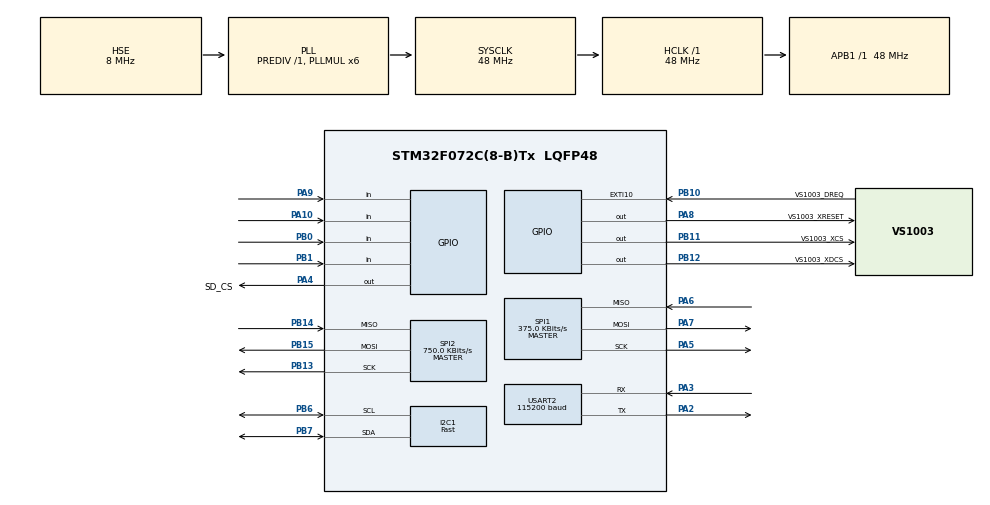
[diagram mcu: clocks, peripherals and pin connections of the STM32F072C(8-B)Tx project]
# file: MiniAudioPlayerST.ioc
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Dma.Request0=SPI1_RX
Dma.Request1=SPI1_TX
Dma.Request2=SPI2_TX
Dma.SPI1_RX.0.Direction=DMA_PERIPH_TO_MEMORY
Dma.SPI1_RX.0.Instance=DMA1_Channel2
Dma.SPI1_RX.0.MemDataAlignment=DMA_MDATAALIGN_BYTE
Dma.SPI1_RX.0.MemInc=DMA_MINC_ENABLE
Dma.SPI1_RX.0.Mode=DMA_NORMAL
Dma.SPI1_RX.0.PeriphDataAlignment=DMA_PDATAALIGN_BYTE
Dma.SPI1_RX.0.PeriphInc=DMA_PINC_DISABLE
Dma.SPI1_RX.0.Priority=DMA_PRIORITY_HIGH
Dma.SPI1_TX.1.Direction=DMA_MEMORY_TO_PERIPH
Dma.SPI1_TX.1.Instance=DMA1_Channel3
Dma.SPI1_TX.1.MemDataAlignment=DMA_MDATAALIGN_BYTE
Dma.SPI1_TX.1.MemInc=DMA_MINC_DISABLE
Dma.SPI1_TX.1.Mode=DMA_NORMAL
Dma.SPI1_TX.1.PeriphDataAlignment=DMA_PDATAALIGN_BYTE
Dma.SPI1_TX.1.PeriphInc=DMA_PINC_DISABLE
Dma.SPI1_TX.1.Priority=DMA_PRIORITY_HIGH
Dma.SPI2_TX.2.Direction=DMA_MEMORY_TO_PERIPH
Dma.SPI2_TX.2.Instance=DMA1_Channel5
Dma.SPI2_TX.2.MemDataAlignment=DMA_MDATAALIGN_BYTE
Dma.SPI2_TX.2.MemInc=DMA_MINC_ENABLE
Dma.SPI2_TX.2.Mode=DMA_NORMAL
Dma.SPI2_TX.2.PeriphDataAlignment=DMA_PDATAALIGN_BYTE
Dma.SPI2_TX.2.PeriphInc=DMA_PINC_DISABLE
Dma.SPI2_TX.2.Priority=DMA_PRIORITY_VERY_HIGH
FATFS._CODE_PAGE=437
FATFS._FS_NORTC=1
FATFS._LFN_UNICODE=1
FATFS._NORTC_MDAY=24
FATFS._NORTC_MON=6
FATFS._NORTC_YEAR=2026
FATFS._USE_FASTSEEK=0
FATFS._USE_LFN=1
FATFS._USE_MKFS=0
FATFS._USE_STRFUNC=0
I2C1.I2C_Speed_Mode=I2C_Fast
I2C1.Timing=0x0010020A
Mcu.Family=STM32F0
Mcu.Name=STM32F072C(8-B)Tx
Mcu.Package=LQFP48
NVIC.DMA1_Channel2_3_IRQn=true\:2\:0\:true\:false\:true\:false\:true\:true
NVIC.DMA1_Channel4_5_6_7_IRQn=true\:1\:0\:true\:false\:true\:false\:true\:true
NVIC.EXTI4_15_IRQn=true\:0\:0\:true\:false\:true\:true\:true\:true
NVIC.TIM1_BRK_UP_TRG_COM_IRQn=true\:3\:0\:true\:false\:true\:true\:true\:true
PA10.GPIO_PuPd=GPIO_PULLUP
PA10.Signal=GPIO_Input
PA13.Mode=Serial_Wire
PA13.Signal=SYS_SWDIO
PA14.Mode=Serial_Wire
PA14.Signal=SYS_SWCLK
PA2.Mode=Asynchronous
PA2.Signal=USART2_TX
PA3.Mode=Asynchronous
PA3.Signal=USART2_RX
PA4.GPIO_Label=SD_CS
PA4.PinState=GPIO_PIN_SET
PA4.Signal=GPIO_Output
PA5.Mode=Full_Duplex_Master
PA5.Signal=SPI1_SCK
PA6.Mode=Full_Duplex_Master
PA6.Signal=SPI1_MISO
PA7.Mode=Full_Duplex_Master
PA7.Signal=SPI1_MOSI
PA8.GPIO_Label=VS1003_XRESET
PA8.Signal=GPIO_Output
PA9.GPIO_PuPd=GPIO_PULLUP
PA9.Signal=GPIO_Input
PB0.GPIO_PuPd=GPIO_PULLUP
PB0.Signal=GPIO_Input
PB1.GPIO_PuPd=GPIO_PULLUP
PB1.Signal=GPIO_Input
PB10.GPIO_Label=VS1003_DREQ
PB10.Signal=GPXTI10
PB11.GPIO_Label=VS1003_XCS
PB11.GPIO_PuPd=GPIO_NOPULL
PB11.PinState=GPIO_PIN_SET
PB11.Signal=GPIO_Output
PB12.GPIO_Label=VS1003_XDCS
PB12.PinState=GPIO_PIN_SET
PB12.Signal=GPIO_Output
PB13.Mode=Full_Duplex_Master
PB13.Signal=SPI2_SCK
PB14.Mode=Full_Duplex_Master
PB14.Signal=SPI2_MISO
PB15.Mode=Full_Duplex_Master
PB15.Signal=SPI2_MOSI
PB6.Mode=I2C
PB6.Signal=I2C1_SCL
PB7.Mode=I2C
PB7.Signal=I2C1_SDA
PF0-OSC_IN.Mode=HSE-External-Oscillator
PF0-OSC_IN.Signal=RCC_OSC_IN
PF1-OSC_OUT.Mode=HSE-External-Oscillator
PF1-OSC_OUT.Signal=RCC_OSC_OUT
ProjectManager.HeapSize=0x200
ProjectManager.StackSize=0x800
ProjectManager.TargetToolchain=MDK-ARM V5.32
RCC.AHBFreq_Value=48000000
RCC.APB1Freq_Value=48000000
RCC.APB1TimFreq_Value=48000000
RCC.HCLKFreq_Value=48000000
RCC.PLLMUL=RCC_PLL_MUL6
RCC.PLLSourceVirtual=RCC_PLLSOURCE_HSE
RCC.SYSCLKFreq_VALUE=48000000
RCC.SYSCLKSource=RCC_SYSCLKSOURCE_PLLCLK
SPI1.BaudRatePrescaler=SPI_BAUDRATEPRESCALER_128
SPI1.CalculateBaudRate=375.0 KBits/s
SPI1.DataSize=SPI_DATASIZE_8BIT
SPI1.Direction=SPI_DIRECTION_2LINES
SPI1.Mode=SPI_MODE_MASTER
SPI1.NSSPMode=SPI_NSS_PULSE_DISABLE
SPI1.VirtualType=VM_MASTER
SPI2.BaudRatePrescaler=SPI_BAUDRATEPRESCALER_64
SPI2.CalculateBaudRate=750.0 KBits/s
SPI2.DataSize=SPI_DATASIZE_8BIT
SPI2.Direction=SPI_DIRECTION_2LINES
SPI2.Mode=SPI_MODE_MASTER
SPI2.NSSPMode=SPI_NSS_PULSE_DISABLE
SPI2.VirtualType=VM_MASTER
TIM1.AutoReloadPreload=TIM_AUTORELOAD_PRELOAD_ENABLE
TIM1.Period=99
TIM1.Prescaler=4799
USART2.BaudRate=115200
USART2.VirtualMode-Asynchronous=VM_ASYNC
VP_FATFS_VS_Generic.Mode=User_defined
VP_TIM1_VS_ClockSourceINT.Mode=Internal
board=custom

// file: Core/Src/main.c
/* USER CODE BEGIN Header */
/**
  ******************************************************************************
  * @file           : main.c
  * @brief          : Main program body
  ******************************************************************************
  * @attention
  *
  * Copyright (c) 2026 STMicroelectronics.
  * All rights reserved.
  *
  * This software is licensed under terms that can be found in the LICENSE file
  * in the root directory of this software component.
  * If no LICENSE file comes with this software, it is provided AS-IS.
  *
  ******************************************************************************
  */
/* USER CODE END Header */
#include "main.h"
#include "dma.h"
#include "fatfs.h"
#include "i2c.h"
#include "spi.h"
#include "tim.h"
#include "usart.h"
#include "gpio.h"

/* USER CODE BEGIN Includes */
#include "test_main.h"
#if !TEST_MAIN_ENABLED
#include "app.h"
#endif
/* USER CODE END Includes */

void SystemClock_Config(void);

int main(void)
{

  /* MCU Configuration--------------------------------------------------------*/

  /* Reset of all peripherals, Initializes the Flash interface and the Systick. */
  HAL_Init();

  /* Configure the system clock */
  SystemClock_Config();

  /* Initialize all configured peripherals */
  MX_GPIO_Init();
  MX_DMA_Init();
  MX_I2C1_Init();
  MX_USART2_UART_Init();
  MX_TIM1_Init();
  MX_SPI1_Init();
  MX_FATFS_Init();
  MX_SPI2_Init();
  /* USER CODE BEGIN 2 */
#if TEST_MAIN_ENABLED
  Test_Init();
#else
  App_Init();
#endif

  /* USER CODE END 2 */

  /* Infinite loop */
  while (1)
  {

    /* USER CODE BEGIN 3 */
#if TEST_MAIN_ENABLED
    Test_Run();
#else
    App_Run();
#endif
  }
  /* USER CODE END 3 */
}

void SystemClock_Config(void)
{
  RCC_OscInitTypeDef RCC_OscInitStruct = {0};
  RCC_ClkInitTypeDef RCC_ClkInitStruct = {0};
  RCC_PeriphCLKInitTypeDef PeriphClkInit = {0};

  /** Initializes the RCC Oscillators according to the specified parameters
  * in the RCC_OscInitTypeDef structure.
  */
  RCC_OscInitStruct.OscillatorType = RCC_OSCILLATORTYPE_HSI|RCC_OSCILLATORTYPE_HSE;
  RCC_OscInitStruct.HSEState = RCC_HSE_ON;
  RCC_OscInitStruct.HSIState = RCC_HSI_ON;
  RCC_OscInitStruct.HSICalibrationValue = RCC_HSICALIBRATION_DEFAULT;
  RCC_OscInitStruct.PLL.PLLState = RCC_PLL_ON;
  RCC_OscInitStruct.PLL.PLLSource = RCC_PLLSOURCE_HSE;
  RCC_OscInitStruct.PLL.PLLMUL = RCC_PLL_MUL6;
  RCC_OscInitStruct.PLL.PREDIV = RCC_PREDIV_DIV1;
  if (HAL_RCC_OscConfig(&RCC_OscInitStruct) != HAL_OK)
  {
    Error_Handler();
  }

  /** Initializes the CPU, AHB and APB buses clocks
  */
  RCC_ClkInitStruct.ClockType = RCC_CLOCKTYPE_HCLK|RCC_CLOCKTYPE_SYSCLK
                              |RCC_CLOCKTYPE_PCLK1;
  RCC_ClkInitStruct.SYSCLKSource = RCC_SYSCLKSOURCE_PLLCLK;
  RCC_ClkInitStruct.AHBCLKDivider = RCC_SYSCLK_DIV1;
  RCC_ClkInitStruct.APB1CLKDivider = RCC_HCLK_DIV1;

  if (HAL_RCC_ClockConfig(&RCC_ClkInitStruct, FLASH_LATENCY_1) != HAL_OK)
  {
    Error_Handler();
  }
  PeriphClkInit.PeriphClockSelection = RCC_PERIPHCLK_USART2|RCC_PERIPHCLK_I2C1;
  PeriphClkInit.Usart2ClockSelection = RCC_USART2CLKSOURCE_PCLK1;
  PeriphClkInit.I2c1ClockSelection = RCC_I2C1CLKSOURCE_HSI;
  if (HAL_RCCEx_PeriphCLKConfig(&PeriphClkInit) != HAL_OK)
  {
    Error_Handler();
  }
}

void Error_Handler(void)
{
  __disable_irq();
  while (1)
  {
  }
}
